# AT90PWM1 device description
Architecture: AVR8; Family: megaAVR
Registers are 8-bit, access not given, no defined reset value unless marked. A register's access mark holds for its fields unless they carry their own. Offsets are from the block's base; [hi:lo] are bit positions; {n}, {i} and the like mark numbered series.

## ADC — Analog-to-Digital Converter
Instances: ADC 0x00
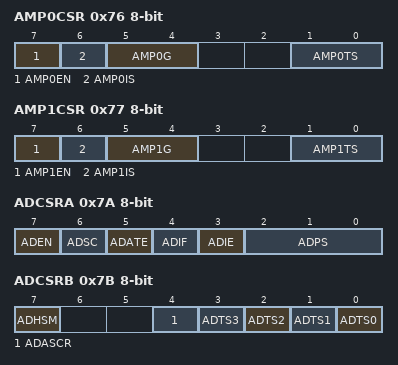
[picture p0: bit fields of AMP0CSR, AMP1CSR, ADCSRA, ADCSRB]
0x76 AMP0CSR
  [7] AMP0EN, [6] AMP0IS, [5:4] AMP0G, [1:0] AMP0TS
0x77 AMP1CSR
  [7] AMP1EN, [6] AMP1IS, [5:4] AMP1G, [1:0] AMP1TS
0x78 ADC 16-bit — ADC Data Register Bytes
0x7A ADCSRA — The ADC Control and Status register
  [7] ADEN — ADC Enable
  [6] ADSC — ADC Start Conversion
  [5] ADATE — ADC Auto Trigger Enable
  [4] ADIF — ADC Interrupt Flag
  [3] ADIE — ADC Interrupt Enable
  [2:0] ADPS — ADC Prescaler Select Bits
0x7B ADCSRB — ADC Control and Status Register B
  [7] ADHSM — ADC High Speed Mode
  [4] ADASCR — ADC Start Conversion
  [n] ADTS{n} (n=0..3) — ADC Auto Trigger Source Selection {n}
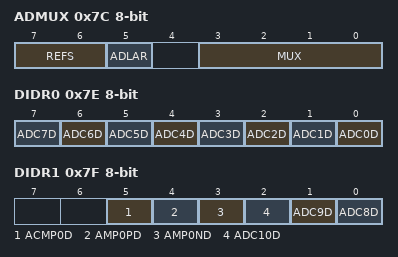
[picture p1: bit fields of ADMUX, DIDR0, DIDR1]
0x7C ADMUX — The ADC multiplexer Selection Register
  [7:6] REFS — Reference Selection Bits
    0=AREF, Internal Vref turned off; 1=AVCC with external capacitor at AREF pin; 3=Internal 2.56V Voltage Reference with external capacitor at AREF pin
  [5] ADLAR — Left Adjust Result
  [3:0] MUX — Analog Channel and Gain Selection Bits
0x7E DIDR0 — Digital Input Disable Register 0
  [n] ADC{n}D (n=0..7)
0x7F DIDR1 — Digital Input Disable Register 1
  [5] ACMP0D, [4] AMP0PD, [3] AMP0ND, [2] ADC10D, [1] ADC9D, [0] ADC8D

## SPI — Serial Peripheral Interface
Instances: SPI 0x00
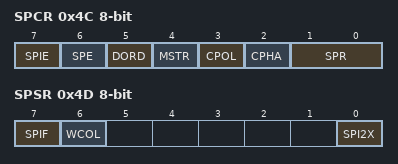
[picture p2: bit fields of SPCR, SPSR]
0x4C SPCR — SPI Control Register
  [7] SPIE — SPI Interrupt Enable
  [6] SPE — SPI Enable
  [5] DORD — Data Order
  [4] MSTR — Master/Slave Select
  [3] CPOL — Clock polarity
  [2] CPHA — Clock Phase
  [1:0] SPR — SPI Clock Rate Selects
    0=fosc/4; 1=fosc/16; 2=fosc/64; 3=fosc/128; 4=fosc/2; 5=fosc/8; 6=fosc/32; 7=fosc/64
0x4D SPSR — SPI Status Register
  [7] SPIF — SPI Interrupt Flag
  [6] WCOL — Write Collision Flag
  [0] SPI2X — Double SPI Speed Bit
0x4E SPDR — SPI Data Register
  [7:0] SPD — SPI Data

## WDT — Watchdog Timer
Instances: WDT 0x00
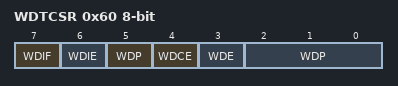
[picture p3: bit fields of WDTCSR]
0x60 WDTCSR — Watchdog Timer Control Register
  [7] WDIF — Watchdog Timeout Interrupt Flag
  [6] WDIE — Watchdog Timeout Interrupt Enable
  [4] WDCE — Watchdog Change Enable
  [3] WDE — Watch Dog Enable
  [5,2:0] WDP — Watchdog Timer Prescaler Bits
    0=Oscillator Cycles 2K; 1=Oscillator Cycles 4K; 2=Oscillator Cycles 8K; 3=Oscillator Cycles 16K; 4=Oscillator Cycles 32K; 5=Oscillator Cycles 64K; 6=Oscillator Cycles 128K; 7=Oscillator Cycles 256K; 8=Oscillator Cycles 512K; 9=Oscillator Cycles 1024K

## EXINT — External Interrupts
Instances: EXINT 0x00
0x3C EIFR — External Interrupt Flag Register
  [3:0] INTF — External Interrupt Flags
0x3D EIMSK — External Interrupt Mask Register
  [3:0] INT — External Interrupt Mask
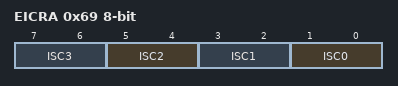
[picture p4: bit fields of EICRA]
0x69 EICRA — External Interrupt Control Register A
  [all] fields
    0=Low Level of INTX; 1=Any Logical Change of INTX; 2=Falling Edge of INTX; 3=Rising Edge of INTX
  [2n+1:2n] ISC{n} (n=0..3) — External Interrupt Sense Control Bit

## EEPROM
Instances: EEPROM 0x00
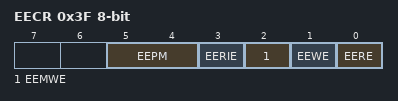
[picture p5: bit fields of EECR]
0x3F EECR — EEPROM Control Register
  [5:4] EEPM — EEPROM Programming Mode
  [3] EERIE — EEPROM Ready Interrupt Enable
  [2] EEMWE — EEPROM Master Write Enable
  [1] EEWE — EEPROM Write Enable
  [0] EERE — EEPROM Read Enable
0x40 EEDR — EEPROM Data Register
  [7:0] EEDR — EEPROM Data Bits
0x41 EEAR 16-bit — EEPROM Read/Write Access Bytes
  [11:0] EEAR — EEPROM Address bytes

## AC — Analog Comparator
Instances: AC 0x00
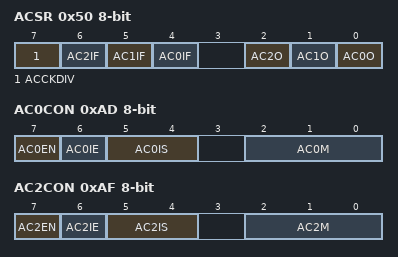
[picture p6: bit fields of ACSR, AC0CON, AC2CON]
0x50 ACSR — Analog Comparator Status Register
  [7] ACCKDIV — Analog Comparator Clock Divider
  [6] AC2IF — Analog Comparator 2 Interrupt Flag Bit
  [5] AC1IF — Analog Comparator 1 Interrupt Flag Bit
  [4] AC0IF — Analog Comparator 0 Interrupt Flag Bit
  [2] AC2O — Analog Comparator 2 Output Bit
  [1] AC1O — Analog Comparator 1 Output Bit
  [0] AC0O — Analog Comparator 0 Output Bit
0xAD AC0CON — Analog Comparator 0 Control Register
  [7] AC0EN — Analog Comparator 0 Enable Bit
  [6] AC0IE — Analog Comparator 0 Interrupt Enable Bit
  [5:4] AC0IS — Analog Comparator 0 Interrupt Select Bit
  [2:0] AC0M — Analog Comparator 0 Multiplexer Register
0xAF AC2CON — Analog Comparator 2 Control Register
  [7] AC2EN — Analog Comparator 2 Enable Bit
  [6] AC2IE — Analog Comparator 2 Interrupt Enable Bit
  [5:4] AC2IS — Analog Comparator 2 Interrupt Select Bit
    0=Interrupt on Toggle; 2=Interrupt on Falling Edge; 3=Interrupt on Rising Edge
  [2:0] AC2M — Analog Comparator 2 Multiplexer Register
